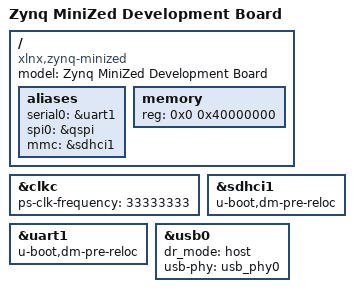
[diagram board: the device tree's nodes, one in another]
/*
 * Xilinx MiniZed board DTS
*/
/dts-v1/;
/include/ "zynq-7000.dtsi"

/ {
	model = "Zynq MiniZed Development Board";
	compatible = "xlnx,zynq-minized", "xlnx,zynq-7000";

	aliases {
		serial0 = &uart1;
                spi0 = &qspi;
                mmc = &sdhci1;
	};

	memory {
		device_type = "memory";
		reg = <0x0 0x40000000>;
	};
};

&clkc {
	ps-clk-frequency = <33333333>;
};

&sdhci1 {
        u-boot,dm-pre-reloc;
	status = "okay";
};

&uart1 {
        u-boot,dm-pre-reloc;
	status = "okay";
};

&usb0 {
	status = "okay";
	dr_mode = "host";
	usb-phy = <&usb_phy0>;
};
